AUTOSAR XML (schema 4-2-2)
package /ComponentTypes
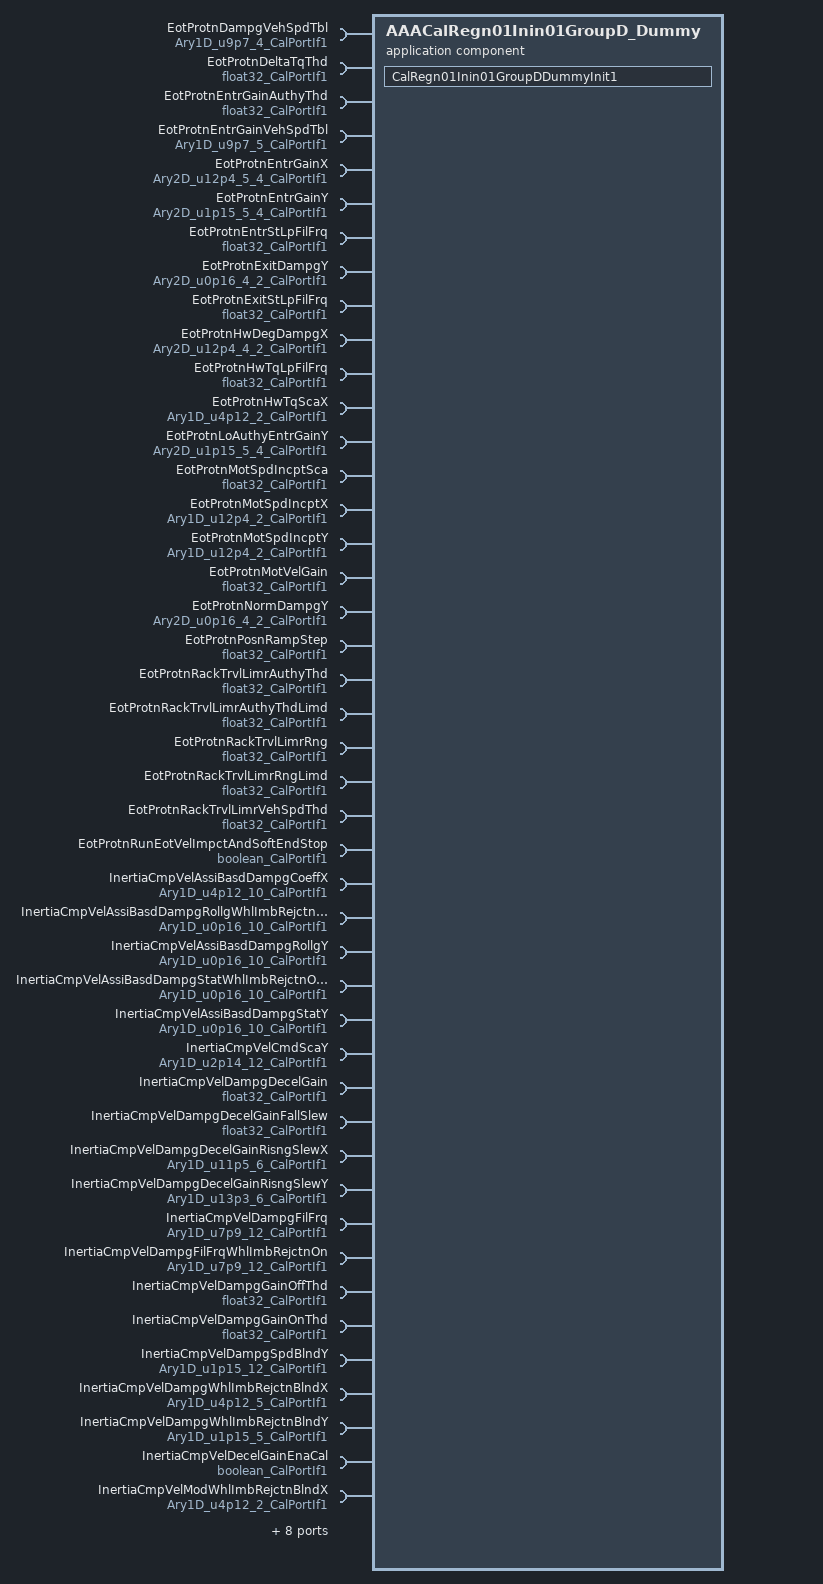
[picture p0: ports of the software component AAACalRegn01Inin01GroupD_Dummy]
  application sw component type AAACalRegn01Inin01GroupD_Dummy
    52 x require port:
      EotProtnDampgVehSpdTbl: parameter-require-com-spec{init-value=[0, 640, 1280, 2560], parameter=Ary1D}, required-interface=Ary1D_u9p7_4_CalPortIf1
      EotProtnDeltaTqThd: parameter-require-com-spec{init-value=0, parameter=Val}, required-interface=float32_CalPortIf1
      EotProtnEntrGainAuthyThd: parameter-require-com-spec{init-value=0.5, parameter=Val}, required-interface=float32_CalPortIf1
      EotProtnEntrGainVehSpdTbl: parameter-require-com-spec{init-value=[0, 640, 1280, 1920, 2560], parameter=Ary1D}, required-interface=Ary1D_u9p7_5_CalPortIf1
      EotProtnEntrGainX: parameter-require-com-spec{init-value=5 x [0, 480, 960, 1440], parameter=Ary2D}, required-interface=Ary2D_u12p4_5_4_CalPortIf1
      EotProtnEntrGainY: parameter-require-com-spec{init-value=5 x [0, 10813, 21627, 32768], parameter=Ary2D}, required-interface=Ary2D_u1p15_5_4_CalPortIf1
      EotProtnEntrStLpFilFrq: parameter-require-com-spec{init-value=30, parameter=Val}, required-interface=float32_CalPortIf1
      EotProtnExitDampgY: parameter-require-com-spec{init-value=[[0, 262], [0, 262], [0, 262], [0, 262]], parameter=Ary2D}, required-interface=Ary2D_u0p16_4_2_CalPortIf1
      EotProtnExitStLpFilFrq: parameter-require-com-spec{init-value=5, parameter=Val}, required-interface=float32_CalPortIf1
      EotProtnHwDegDampgX: parameter-require-com-spec{init-value=[[1920, 0], [1920, 0], [1920, 0], [1920, 0]], parameter=Ary2D}, required-interface=Ary2D_u12p4_4_2_CalPortIf1
      EotProtnHwTqLpFilFrq: parameter-require-com-spec{init-value=30, parameter=Val}, required-interface=float32_CalPortIf1
      EotProtnHwTqScaX: parameter-require-com-spec{init-value=[0, 4096], parameter=Ary1D}, required-interface=Ary1D_u4p12_2_CalPortIf1
      EotProtnLoAuthyEntrGainY: parameter-require-com-spec{init-value=5 x [0, 9830, 22938, 32768], parameter=Ary2D}, required-interface=Ary2D_u1p15_5_4_CalPortIf1
      EotProtnMotSpdIncptSca: parameter-require-com-spec{init-value=0.02, parameter=Val}, required-interface=float32_CalPortIf1
      EotProtnMotSpdIncptX: parameter-require-com-spec{init-value=[800, 400], parameter=Ary1D}, required-interface=Ary1D_u12p4_2_CalPortIf1
      EotProtnMotSpdIncptY: parameter-require-com-spec{init-value=[10400, 10400], parameter=Ary1D}, required-interface=Ary1D_u12p4_2_CalPortIf1
      EotProtnMotVelGain: parameter-require-com-spec{init-value=0.29, parameter=Val}, required-interface=float32_CalPortIf1
      EotProtnNormDampgY: parameter-require-com-spec{init-value=[[0, 262], [0, 262], [0, 262], [0, 262]], parameter=Ary2D}, required-interface=Ary2D_u0p16_4_2_CalPortIf1
      EotProtnPosnRampStep: parameter-require-com-spec{init-value=3, parameter=Val}, required-interface=float32_CalPortIf1
      EotProtnRackTrvlLimrAuthyThd: parameter-require-com-spec{init-value=1, parameter=Val}, required-interface=float32_CalPortIf1
      EotProtnRackTrvlLimrAuthyThdLimd: parameter-require-com-spec{init-value=1, parameter=Val}, required-interface=float32_CalPortIf1
      EotProtnRackTrvlLimrRng: parameter-require-com-spec{init-value=90, parameter=Val}, required-interface=float32_CalPortIf1
      EotProtnRackTrvlLimrRngLimd: parameter-require-com-spec{init-value=20, parameter=Val}, required-interface=float32_CalPortIf1
      EotProtnRackTrvlLimrVehSpdThd: parameter-require-com-spec{init-value=20, parameter=Val}, required-interface=float32_CalPortIf1
      EotProtnRunEotVelImpctAndSoftEndStop: parameter-require-com-spec{init-value=0, parameter=Logl}, required-interface=boolean_CalPortIf1
      InertiaCmpVelAssiBasdDampgCoeffX: parameter-require-com-spec{init-value=[0, 2048, 4096, 6144, 8192, 10240, 12288, 14336, 16384, 18432], parameter=Ary1D}, required-interface=Ary1D_u4p12_10_CalPortIf1
      InertiaCmpVelAssiBasdDampgRollgWhlImbRejctnOnY: parameter-require-com-spec{init-value=10 x 0, parameter=Ary1D}, required-interface=Ary1D_u0p16_10_CalPortIf1
      InertiaCmpVelAssiBasdDampgRollgY: parameter-require-com-spec{init-value=10 x 0, parameter=Ary1D}, required-interface=Ary1D_u0p16_10_CalPortIf1
      InertiaCmpVelAssiBasdDampgStatWhlImbRejctnOnY: parameter-require-com-spec{init-value=10 x 0, parameter=Ary1D}, required-interface=Ary1D_u0p16_10_CalPortIf1
      InertiaCmpVelAssiBasdDampgStatY: parameter-require-com-spec{init-value=10 x 0, parameter=Ary1D}, required-interface=Ary1D_u0p16_10_CalPortIf1
      InertiaCmpVelCmdScaY: parameter-require-com-spec{init-value=12 x 384, parameter=Ary1D}, required-interface=Ary1D_u2p14_12_CalPortIf1
      InertiaCmpVelDampgDecelGain: parameter-require-com-spec{init-value=1, parameter=Val}, required-interface=float32_CalPortIf1
      InertiaCmpVelDampgDecelGainFallSlew: parameter-require-com-spec{init-value=-4500, parameter=Val}, required-interface=float32_CalPortIf1
      InertiaCmpVelDampgDecelGainRisngSlewX: parameter-require-com-spec{init-value=[0, 640, 1088, 1120, 1152, 1184], parameter=Ary1D}, required-interface=Ary1D_u11p5_6_CalPortIf1
      InertiaCmpVelDampgDecelGainRisngSlewY: parameter-require-com-spec{init-value=6 x 36000, parameter=Ary1D}, required-interface=Ary1D_u13p3_6_CalPortIf1
      InertiaCmpVelDampgFilFrq: parameter-require-com-spec{init-value=12 x 8192, parameter=Ary1D}, required-interface=Ary1D_u7p9_12_CalPortIf1
      InertiaCmpVelDampgFilFrqWhlImbRejctnOn: parameter-require-com-spec{init-value=12 x 8192, parameter=Ary1D}, required-interface=Ary1D_u7p9_12_CalPortIf1
      InertiaCmpVelDampgGainOffThd: parameter-require-com-spec{init-value=1, parameter=Val}, required-interface=float32_CalPortIf1
      InertiaCmpVelDampgGainOnThd: parameter-require-com-spec{init-value=10, parameter=Val}, required-interface=float32_CalPortIf1
      InertiaCmpVelDampgSpdBlndY: parameter-require-com-spec{init-value=[32768, 32768, 9830, 6554, 3277, 0, 0, 0, 0, 0, 0, 0], parameter=Ary1D}, required-interface=Ary1D_u1p15_12_CalPortIf1
      InertiaCmpVelDampgWhlImbRejctnBlndX: parameter-require-com-spec{init-value=[208, 432, 640, 848, 1056], parameter=Ary1D}, required-interface=Ary1D_u4p12_5_CalPortIf1
      InertiaCmpVelDampgWhlImbRejctnBlndY: parameter-require-com-spec{init-value=5 x 0, parameter=Ary1D}, required-interface=Ary1D_u1p15_5_CalPortIf1
      InertiaCmpVelDecelGainEnaCal: parameter-require-com-spec{init-value=0, parameter=Logl}, required-interface=boolean_CalPortIf1
      InertiaCmpVelModWhlImbRejctnBlndX: parameter-require-com-spec{init-value=[0, 4096], parameter=Ary1D}, required-interface=Ary1D_u4p12_2_CalPortIf1
      InertiaCmpVelModWhlImbRejctnBlndY: parameter-require-com-spec{init-value=[32768, 0], parameter=Ary1D}, required-interface=Ary1D_u1p15_2_CalPortIf1
      InertiaCmpVelMotInertia: parameter-require-com-spec{init-value=0.001, parameter=Val}, required-interface=float32_CalPortIf1
      InertiaCmpVelMotVelBasdOutpScagX: parameter-require-com-spec{init-value=[1005, 1100], parameter=Ary1D}, required-interface=Ary1D_u12p4_2_CalPortIf1
      InertiaCmpVelMotVelBasdOutpScagY: parameter-require-com-spec{init-value=[32768, 32768], parameter=Ary1D}, required-interface=Ary1D_u1p15_2_CalPortIf1
      InertiaCmpVelNotchBlndY: parameter-require-com-spec{init-value=12 x 0, parameter=Ary1D}, required-interface=Ary1D_u1p15_12_CalPortIf1
      InertiaCmpVelNotchFilStruct: parameter-require-com-spec=Rec, required-interface=FilNotchGainRec1_CalPortIf1
      InertiaCmpVelTqSnsrVelFilFrq: parameter-require-com-spec{init-value=20, parameter=Val}, required-interface=float32_CalPortIf1
      InertiaCmpVelTqSnsrVelSca: parameter-require-com-spec{init-value=12 x 0, parameter=Ary1D}, required-interface=Ary1D_u2p14_12_CalPortIf1
    behavior AAACalRegn01Inin01GroupD_Dummy_InternalBehavior: supports-multiple-instantiation=true
      init event AAACalRegn01Inin01GroupD_Dummy_InitEvent: start-on-event=CalRegn01Inin01GroupDDummyInit1
      runnable CalRegn01Inin01GroupDDummyInit1
  swc implementation AAACalRegn01Inin00GroupD_Dummy_Implementation: behavior=AAACalRegn01Inin01GroupD_Dummy_InternalBehavior
    code-descriptors:
      code Default: artifact-descriptors=autosar-engineering-object={short-label=Default, category=SWSRC}
